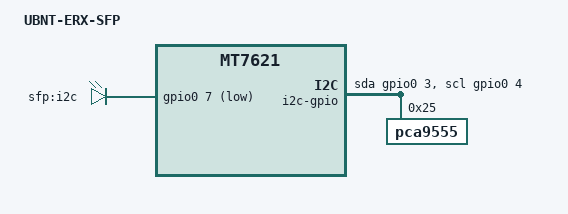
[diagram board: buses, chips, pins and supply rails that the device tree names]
/dts-v1/;

#include "mt7621_ubiquiti_edgerouterx.dtsi"

#include <dt-bindings/gpio/gpio.h>

/ {
	model = "UBNT-ERX-SFP";
	compatible = "ubiquiti,edgerouterx-sfp", "mediatek,mt7621-soc";

	i2c-gpio {
		compatible = "i2c-gpio";
		gpios = <&gpio0 3 GPIO_ACTIVE_HIGH /* sda */
		         &gpio0 4 GPIO_ACTIVE_HIGH /* scl */
		        >;
		#address-cells = <1>;
		#size-cells = <0>;

		pca9555@25 {
			compatible = "pca9555";
			reg = <0x25>;
		};
	};

	leds {
		compatible = "gpio-leds";

		/* Fixme: Currently a hack to enable SFP clk gate. */
		sfp {
			label = "sfp:i2c";
			gpios = <&gpio0 7 GPIO_ACTIVE_LOW>;
			default-state = "off";
			linux,default-trigger = "default-on";
		};
	};
};

&gsw {
	ports {
		lan5: port@5 {
			reg = <5>;
			phy-address = <7>;
			phy-mode = "rgmii-rxid";
		};
	};
};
